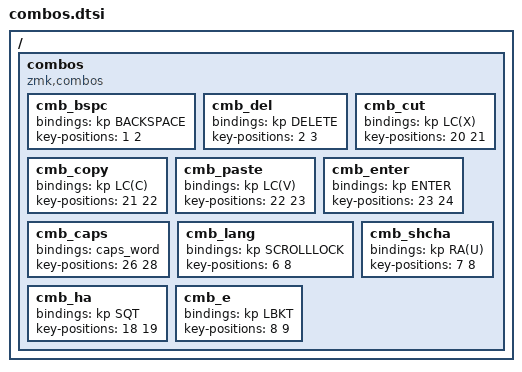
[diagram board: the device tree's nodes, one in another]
//  0  1  2  3  4       5  6  7  8  9
// 10 11 12 13 14      15 16 17 18 19
// 20 21 22 23 24      25 26 27 28 29
//       30 31 32      33 34 35

/ {
    combos {
        compatible = "zmk,combos";

        cmb_bspc {
            bindings = <&kp BACKSPACE>;
            key-positions = <1 2>;
        };

        cmb_del {
            bindings = <&kp DELETE>;
            key-positions = <2 3>;
        };

        cmb_cut {
            bindings = <&kp LC(X)>;
            key-positions = <20 21>;
        };

        cmb_copy {
            bindings = <&kp LC(C)>;
            key-positions = <21 22>;
        };

        cmb_paste {
            bindings = <&kp LC(V)>;
            key-positions = <22 23>;
        };

        cmb_enter {
            bindings = <&kp ENTER>;
            key-positions = <23 24>;
        };

        cmb_caps {
            bindings = <&caps_word>;
            key-positions = <26 28>;
        };

        cmb_lang {
            bindings = <&kp SCROLLLOCK>;
            key-positions = <6 8>;
        };

        cmb_shcha {
            bindings = <&kp RA(U)>;
            key-positions = <7 8>;
        };

        cmb_ha {
            bindings = <&kp SQT>;
            key-positions = <18 19>;
        };

        cmb_e {
            bindings = <&kp LBKT>;
            key-positions = <8 9>;
        };
    };
};
